# SF32LB58x register map
File version: 1.0
CPU: CM33 r0p1, little endian, MPU, FPU, 3 interrupt priority bits
Registers are 32-bit, read-write, reset 0x0 unless marked. A register's access mark holds for its fields unless they carry their own. Offsets are from the block's base; [hi:lo] are bit positions.

## V2D_GPU
Base 0x40088000
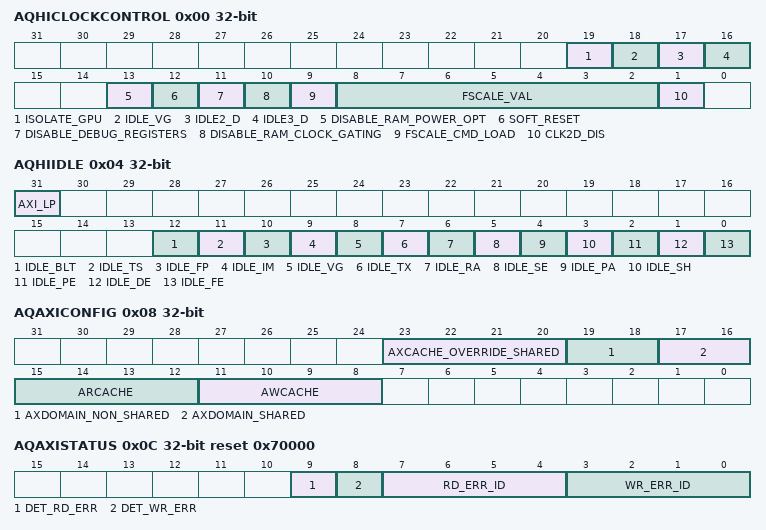
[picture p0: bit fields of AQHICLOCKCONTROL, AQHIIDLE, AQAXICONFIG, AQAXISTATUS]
0x00 AQHICLOCKCONTROL
  [19] ISOLATE_GPU — Isolate GPU bit, used for power on/power off.
  [18] IDLE_VG — VG pipe is idle.
  [17] IDLE2_D — 2D pipe is idle or not present.
  [16] IDLE3_D — 3D pipe is idle or not present.
  [13] DISABLE_RAM_POWER_OPT — disables ram power optimization.
  [12] SOFT_RESET — Soft resets the IP.
  [11] DISABLE_DEBUG_REGISTERS — Disable debug registers. If this bit is 1, debug registers are clock gated.
  [10] DISABLE_RAM_CLOCK_GATING — Disable s clock gating for rams.
  [9] FSCALE_CMD_LOAD — Core clock frequency scale value enable. When writing a 1 to this bit, it updates the frequency scale factore with the value FSCALE_VAL. The bit must be set back to 0 after that. If this bit is set and FSCALE_VAL=0(an invalid combination), the HREADYOUT output signal will get stuck to 0.
  [8:2] FSCALE_VAL — Core clock frequency scale value
  [1] CLK2D_DIS — Disable 2D/VG clock. CLK2D_DIS should be controlled by software. The AXI interface clock is the only block not stalled at that point
0x04 AQHIIDLE
  [31] AXI_LP — AXI is in low power mode
  [12] IDLE_BLT — BLT is idle or not present.
  [11] IDLE_TS — TS(Tessellation Engine):1=TS is idle.
  [10] IDLE_FP — FP is idle or not present
  [9] IDLE_IM — IM(Image Engine):1=IM is idle.
  [8] IDLE_VG — VG(Vector Graphics Engine):1=VG is idle.
  [7] IDLE_TX — TX is idle or not present.
  [6] IDLE_RA — RA is idle or not present.
  [5] IDLE_SE — SE is idle or not present.
  [4] IDLE_PA — PA is idle or not present.
  [3] IDLE_SH — SH is idle or not present.
  [2] IDLE_PE — PE(Pixel Engine):1=PE is idle.
  [1] IDLE_DE — DE is idle or not present.
  [0] IDLE_FE — FE(Fetch Engine):0=FE is busy; 1=FE is idle.
0x08 AQAXICONFIG
  [23:20] AXCACHE_OVERRIDE_SHARED — Configure AxCACHE value for shareable request. Not used for VG cores.
  [19:18] AXDOMAIN_NON_SHARED — Configure AxDOMAIN value for non-shareable request. Not used for VG cores.
  [17:16] AXDOMAIN_SHARED — Configure AxDOMAIN value for shareable request. Not used for VG cores.
  [15:12] ARCACHE — ARCACHE[3:0] value
  [11:8] AWCACHE — AWCACHE[3:0] value
0x0C AQAXISTATUS reset 0x70000
  [9] DET_RD_ERR — 1=A read error is detected.
  [8] DET_WR_ERR — 1=A write error is detected.
  [7:4] RD_ERR_ID — The ID which caused illegal read access error.
  [3:0] WR_ERR_ID — The ID which caused illegal write access error.
0x10 AQINTRACKNOWLEDGE
  [31:0] INTR_VEC — For each interrupt event, 0=Clear, 1=Interrupt Active. For all cores: Bit 31 is AXI_BUS_ERROR. 0=No error, 1=Interrupt Active.
0x14 AQINTRENBL
  [31:0] INTR_ENBL_VEC — 0=Disable Interrupt; 1=Enable Interrupt.
0x24 GCCHIPREV
  [31:0] REV — Revision. This value may vary between releases and can be ignored during test.
0x28 GCCHIPDATE
  [31:0] DATE — Date. This value will vary each release and can be ignored during test.
0x98 GCREGHICHIPPATCHREV
  [7:0] PATCH_REV — Patch Revision. This value will vary each release and can be ignored during test.
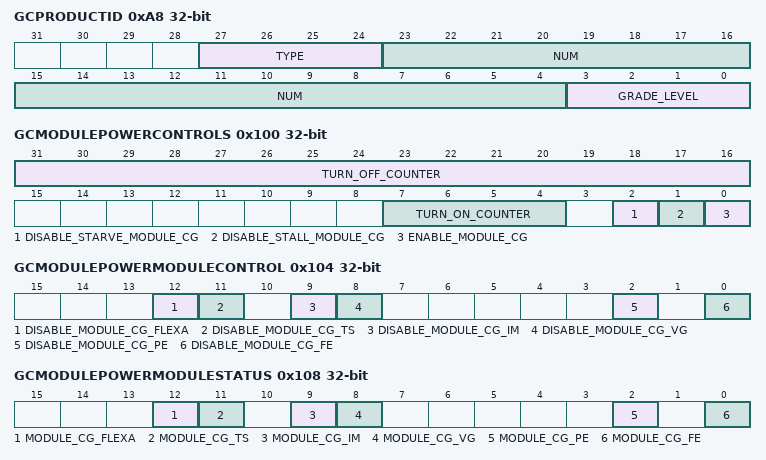
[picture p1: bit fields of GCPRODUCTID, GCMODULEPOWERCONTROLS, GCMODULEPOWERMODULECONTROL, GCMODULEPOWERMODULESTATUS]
0xA8 GCPRODUCTID
  [27:24] TYPE — 0: None-no extra letter on the product name for this core.
  [23:4] NUM — Product number is 265.
  [3:0] GRADE_LEVEL — Product Type is 3: VG(Vectore Graphics).
0x100 GCMODULEPOWERCONTROLS
  [31:16] TURN_OFF_COUNTER — Counter value for clock gating the module if the moduel is idle for this amount of clock cycles.
  [7:4] TURN_ON_COUNTER — Number of clock cycles to wait after turning on the clock
  [2] DISABLE_STARVE_MODULE_CG — Disables module level clock gating for starve/idle condition.
  [1] DISABLE_STALL_MODULE_CG — Disable module level clock gating for stall condition.
  [0] ENABLE_MODULE_CG — Enables module level clock gating
0x104 GCMODULEPOWERMODULECONTROL
  [12] DISABLE_MODULE_CG_FLEXA — Disable module level clock gating for Flexa. Not supported for all variants.
  [11] DISABLE_MODULE_CG_TS — Disables module level clock gating for TS.
  [9] DISABLE_MODULE_CG_IM — Disables module level clock gating for IM.
  [8] DISABLE_MODULE_CG_VG — Disables module level clock gating for VG.
  [2] DISABLE_MODULE_CG_PE — Disables module level clock gating for PE.
  [0] DISABLE_MODULE_CG_FE — Disables module level clock gating for FE.
0x108 GCMODULEPOWERMODULESTATUS
  [12] MODULE_CG_FLEXA — Module level clock gating is ON for Flexa. Not supported for all variants.
  [11] MODULE_CG_TS — Module level clock gating is ON for TS.
  [9] MODULE_CG_IM — Module level clock gating is ON for IM.
  [8] MODULE_CG_VG — Module level clock gating is ON for VG.
  [2] MODULE_CG_PE — Module level clock gating is ON for PE.
  [0] MODULE_CG_FE — Module level clock gating is ON for FE.
0x400 AQMEMORYFEPAGETABLE
  [31:12] BASE_ADDRESS — Base address for the FE vertual address lookup table.
0x414 AQMEMORYDEBUG
  [7:0] MAX_OUTSTANDING_READS — Limits the total number of outstanding read requests.
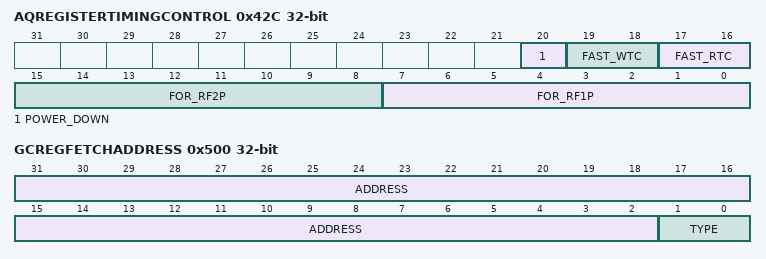
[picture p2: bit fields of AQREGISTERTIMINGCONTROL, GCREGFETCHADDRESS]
0x42C AQREGISTERTIMINGCONTROL
  [20] POWER_DOWN — Powerdown memory.
  [19:18] FAST_WTC — WTC for fast rams.
  [17:16] FAST_RTC — RTC for fast rams.
  [15:8] FOR_RF2P — For 2 port ram.
  [7:0] FOR_RF1P — For 1 port ram.
0x500 GCREGFETCHADDRESS
  [31:2] ADDRESS — Fetch Command Buffer Base Address Register. Must be 64-byte aligned.
  [1:0] TYPE — 0: SYSTEM 1: LOCAL 2: VIRTUAL
0x504 GCREGFETCHCONTROL
  [20:0] COUNT — Number of 64-bit words to fetch. 21 bits is enough for 16MB.
0x508 GCREGCURRENTFETCHADDRESS
  [31:0] ADDRESS — Current Fetch Command Address Register. Debugging register that defines the current address the FE is fetching data from. Read Only.
